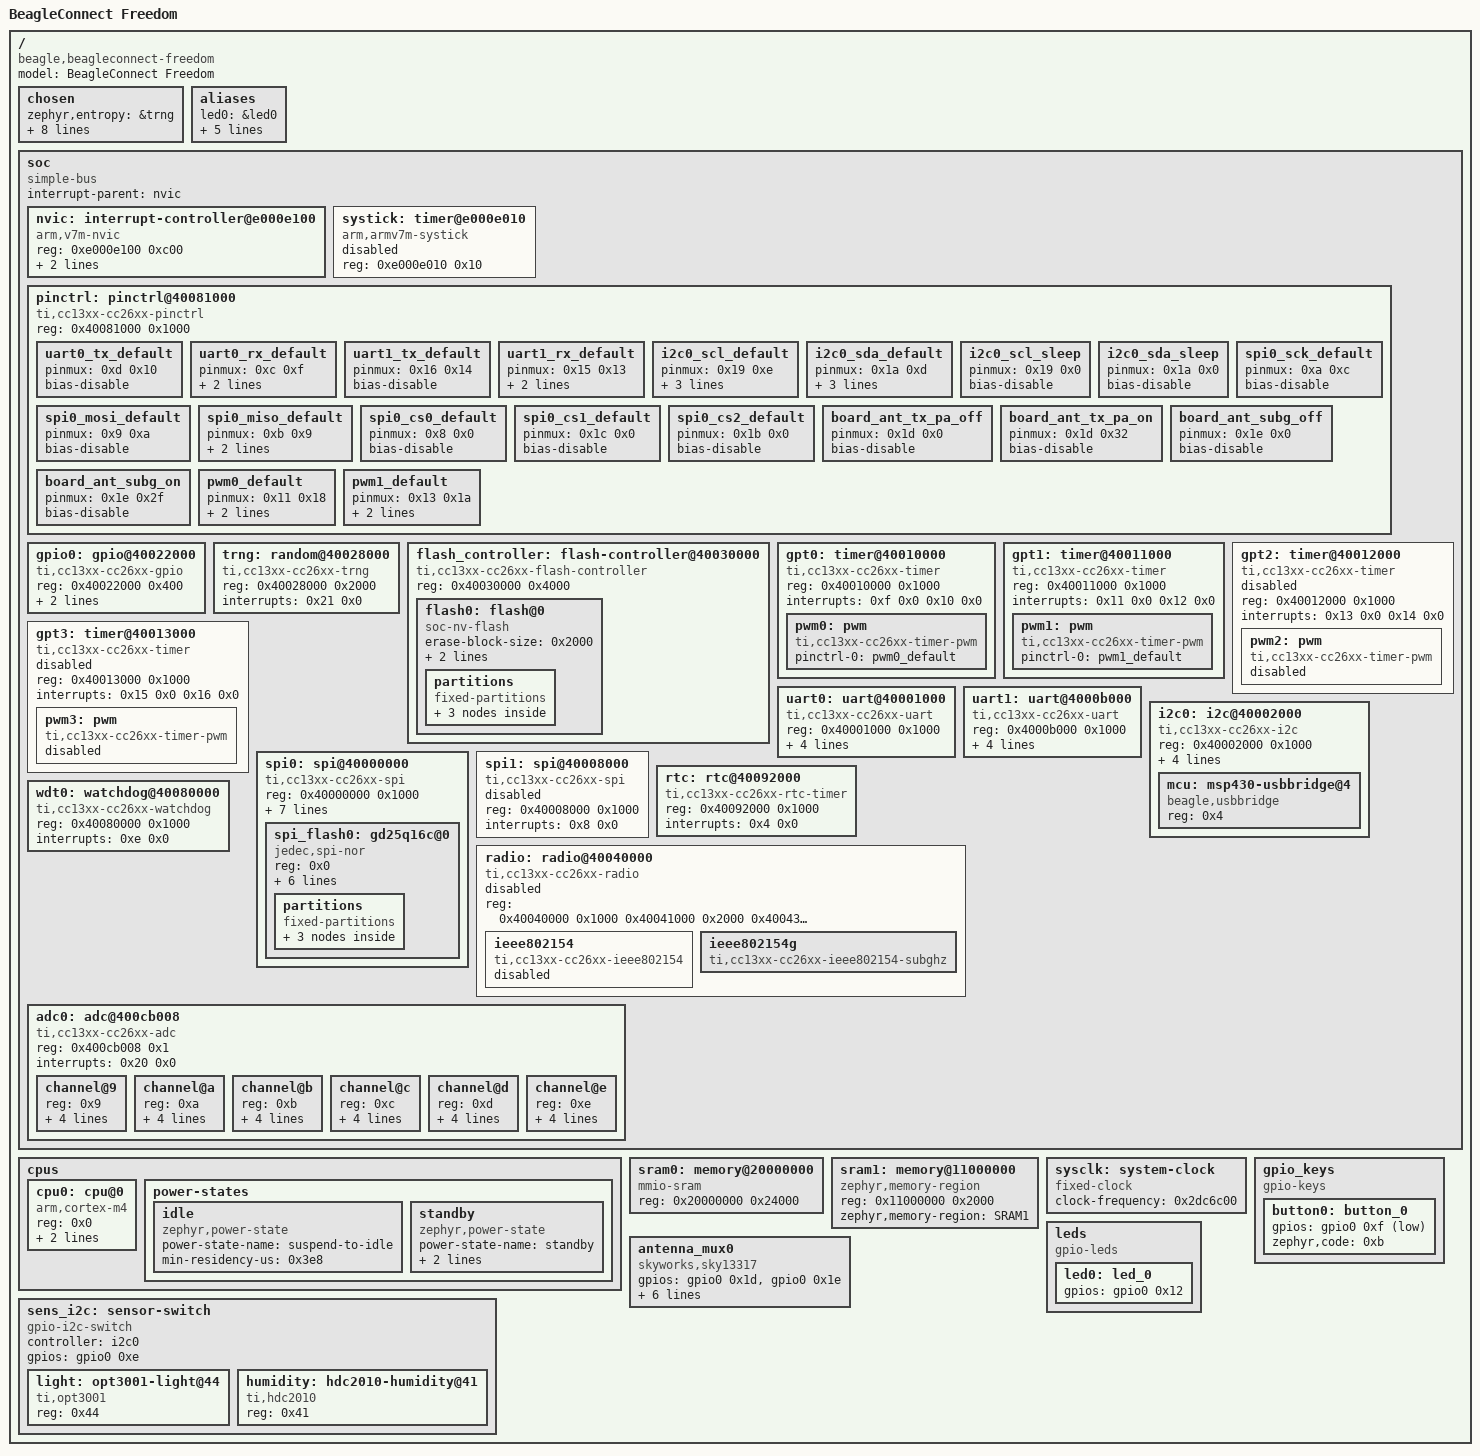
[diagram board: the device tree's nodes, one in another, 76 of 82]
/dts-v1/;

/* node '/' defined in zephyr/dts/common/skeleton.dtsi:9 */
/ {
	#address-cells = < 0x1 >;                    /* in zephyr/dts/common/skeleton.dtsi:10 */
	#size-cells = < 0x1 >;                       /* in zephyr/dts/common/skeleton.dtsi:11 */
	model = "BeagleConnect Freedom";             /* in zephyr/boards/beagle/beagleconnect_freedom/beagleconnect_freedom.dts:17 */
	compatible = "beagle,beagleconnect-freedom"; /* in zephyr/boards/beagle/beagleconnect_freedom/beagleconnect_freedom.dts:18 */

	/* node '/chosen' defined in zephyr/dts/common/skeleton.dtsi:13 */
	chosen {
		zephyr,entropy = &trng;                      /* in zephyr/dts/arm/ti/cc13xx_cc26xx.dtsi:15 */
		zephyr,flash-controller = &flash_controller; /* in zephyr/dts/arm/ti/cc13xx_cc26xx.dtsi:16 */
		zephyr,sram = &sram0;                        /* in zephyr/boards/beagle/beagleconnect_freedom/beagleconnect_freedom.dts:30 */
		zephyr,console = &uart0;                     /* in zephyr/boards/beagle/beagleconnect_freedom/beagleconnect_freedom.dts:31 */
		zephyr,shell-uart = &uart0;                  /* in zephyr/boards/beagle/beagleconnect_freedom/beagleconnect_freedom.dts:32 */
		zephyr,flash = &flash0;                      /* in zephyr/boards/beagle/beagleconnect_freedom/beagleconnect_freedom.dts:33 */
		zephyr,ieee802154 = &ieee802154g;            /* in zephyr/boards/beagle/beagleconnect_freedom/beagleconnect_freedom.dts:34 */
		zephyr,code-partition = &slot0_partition;    /* in zephyr/boards/beagle/beagleconnect_freedom/beagleconnect_freedom.dts:35 */
		zephyr,uart-mcumgr = &uart0;                 /* in zephyr/boards/beagle/beagleconnect_freedom/beagleconnect_freedom.dts:36 */
	};

	/* node '/aliases' defined in zephyr/dts/common/skeleton.dtsi:15 */
	aliases {
		led0 = &led0;               /* in zephyr/boards/beagle/beagleconnect_freedom/beagleconnect_freedom.dts:21 */
		sw0 = &button0;             /* in zephyr/boards/beagle/beagleconnect_freedom/beagleconnect_freedom.dts:22 */
		mcuboot-button0 = &button0; /* in zephyr/boards/beagle/beagleconnect_freedom/beagleconnect_freedom.dts:23 */
		sensor0 = &light;           /* in zephyr/boards/beagle/beagleconnect_freedom/beagleconnect_freedom.dts:24 */
		sensor1 = &humidity;        /* in zephyr/boards/beagle/beagleconnect_freedom/beagleconnect_freedom.dts:25 */
		watchdog0 = &wdt0;          /* in zephyr/boards/beagle/beagleconnect_freedom/beagleconnect_freedom.dts:26 */
	};

	/* node '/soc' defined in zephyr/dts/arm/armv7-m.dtsi:6 */
	soc {
		#address-cells = < 0x1 >;     /* in zephyr/dts/arm/armv7-m.dtsi:7 */
		#size-cells = < 0x1 >;        /* in zephyr/dts/arm/armv7-m.dtsi:8 */
		compatible = "simple-bus";    /* in zephyr/dts/arm/armv7-m.dtsi:9 */
		interrupt-parent = < &nvic >; /* in zephyr/dts/arm/armv7-m.dtsi:10 */
		ranges;                       /* in zephyr/dts/arm/armv7-m.dtsi:11 */

		/* node '/soc/interrupt-controller@e000e100' defined in zephyr/dts/arm/armv7-m.dtsi:13 */
		nvic: interrupt-controller@e000e100 {
			#address-cells = < 0x1 >;            /* in zephyr/dts/arm/armv7-m.dtsi:14 */
			compatible = "arm,v7m-nvic";         /* in zephyr/dts/arm/armv7-m.dtsi:15 */
			reg = < 0xe000e100 0xc00 >;          /* in zephyr/dts/arm/armv7-m.dtsi:16 */
			interrupt-controller;                /* in zephyr/dts/arm/armv7-m.dtsi:17 */
			#interrupt-cells = < 0x2 >;          /* in zephyr/dts/arm/armv7-m.dtsi:18 */
			arm,num-irq-priority-bits = < 0x3 >; /* in zephyr/dts/arm/ti/cc13xx_cc26xx.dtsi:246 */
			phandle = < 0x1 >;                   /* in zephyr/dts/arm/armv7-m.dtsi:10 */
		};

		/* node '/soc/timer@e000e010' defined in zephyr/dts/arm/armv7-m.dtsi:21 */
		systick: timer@e000e010 {
			compatible = "arm,armv7m-systick"; /* in zephyr/dts/arm/armv7-m.dtsi:22 */
			reg = < 0xe000e010 0x10 >;         /* in zephyr/dts/arm/armv7-m.dtsi:23 */
			status = "disabled";               /* in zephyr/dts/arm/ti/cc13xx_cc26xx.dtsi:250 */
		};

		/* node '/soc/pinctrl@40081000' defined in zephyr/dts/arm/ti/cc13xx_cc26xx.dtsi:64 */
		pinctrl: pinctrl@40081000 {
			compatible = "ti,cc13xx-cc26xx-pinctrl"; /* in zephyr/dts/arm/ti/cc13xx_cc26xx.dtsi:65 */
			reg = < 0x40081000 0x1000 >;             /* in zephyr/dts/arm/ti/cc13xx_cc26xx.dtsi:66 */

			/* node '/soc/pinctrl@40081000/uart0_tx_default' defined in zephyr/boards/beagle/beagleconnect_freedom/beagleconnect_freedom-pinctrl.dtsi:11 */
			uart0_tx_default: uart0_tx_default {
				pinmux = < 0xd 0x10 >; /* in zephyr/boards/beagle/beagleconnect_freedom/beagleconnect_freedom-pinctrl.dtsi:12 */
				bias-disable;          /* in zephyr/boards/beagle/beagleconnect_freedom/beagleconnect_freedom-pinctrl.dtsi:13 */
				phandle = < 0x6 >;     /* in zephyr/boards/beagle/beagleconnect_freedom/beagleconnect_freedom.dts:138 */
			};

			/* node '/soc/pinctrl@40081000/uart0_rx_default' defined in zephyr/boards/beagle/beagleconnect_freedom/beagleconnect_freedom-pinctrl.dtsi:16 */
			uart0_rx_default: uart0_rx_default {
				pinmux = < 0xc 0xf >; /* in zephyr/boards/beagle/beagleconnect_freedom/beagleconnect_freedom-pinctrl.dtsi:17 */
				bias-disable;         /* in zephyr/boards/beagle/beagleconnect_freedom/beagleconnect_freedom-pinctrl.dtsi:18 */
				input-enable;         /* in zephyr/boards/beagle/beagleconnect_freedom/beagleconnect_freedom-pinctrl.dtsi:19 */
				phandle = < 0x5 >;    /* in zephyr/boards/beagle/beagleconnect_freedom/beagleconnect_freedom.dts:138 */
			};

			/* node '/soc/pinctrl@40081000/uart1_tx_default' defined in zephyr/boards/beagle/beagleconnect_freedom/beagleconnect_freedom-pinctrl.dtsi:23 */
			uart1_tx_default: uart1_tx_default {
				pinmux = < 0x16 0x14 >; /* in zephyr/boards/beagle/beagleconnect_freedom/beagleconnect_freedom-pinctrl.dtsi:24 */
				bias-disable;           /* in zephyr/boards/beagle/beagleconnect_freedom/beagleconnect_freedom-pinctrl.dtsi:25 */
				phandle = < 0x8 >;      /* in zephyr/boards/beagle/beagleconnect_freedom/beagleconnect_freedom.dts:146 */
			};

			/* node '/soc/pinctrl@40081000/uart1_rx_default' defined in zephyr/boards/beagle/beagleconnect_freedom/beagleconnect_freedom-pinctrl.dtsi:28 */
			uart1_rx_default: uart1_rx_default {
				pinmux = < 0x15 0x13 >; /* in zephyr/boards/beagle/beagleconnect_freedom/beagleconnect_freedom-pinctrl.dtsi:29 */
				bias-disable;           /* in zephyr/boards/beagle/beagleconnect_freedom/beagleconnect_freedom-pinctrl.dtsi:30 */
				input-enable;           /* in zephyr/boards/beagle/beagleconnect_freedom/beagleconnect_freedom-pinctrl.dtsi:31 */
				phandle = < 0x7 >;      /* in zephyr/boards/beagle/beagleconnect_freedom/beagleconnect_freedom.dts:146 */
			};

			/* node '/soc/pinctrl@40081000/i2c0_scl_default' defined in zephyr/boards/beagle/beagleconnect_freedom/beagleconnect_freedom-pinctrl.dtsi:35 */
			i2c0_scl_default: i2c0_scl_default {
				pinmux = < 0x19 0xe >; /* in zephyr/boards/beagle/beagleconnect_freedom/beagleconnect_freedom-pinctrl.dtsi:36 */
				bias-pull-up;          /* in zephyr/boards/beagle/beagleconnect_freedom/beagleconnect_freedom-pinctrl.dtsi:37 */
				drive-open-drain;      /* in zephyr/boards/beagle/beagleconnect_freedom/beagleconnect_freedom-pinctrl.dtsi:38 */
				input-enable;          /* in zephyr/boards/beagle/beagleconnect_freedom/beagleconnect_freedom-pinctrl.dtsi:39 */
				phandle = < 0x9 >;     /* in zephyr/boards/beagle/beagleconnect_freedom/beagleconnect_freedom.dts:153 */
			};

			/* node '/soc/pinctrl@40081000/i2c0_sda_default' defined in zephyr/boards/beagle/beagleconnect_freedom/beagleconnect_freedom-pinctrl.dtsi:42 */
			i2c0_sda_default: i2c0_sda_default {
				pinmux = < 0x1a 0xd >; /* in zephyr/boards/beagle/beagleconnect_freedom/beagleconnect_freedom-pinctrl.dtsi:43 */
				bias-pull-up;          /* in zephyr/boards/beagle/beagleconnect_freedom/beagleconnect_freedom-pinctrl.dtsi:44 */
				drive-open-drain;      /* in zephyr/boards/beagle/beagleconnect_freedom/beagleconnect_freedom-pinctrl.dtsi:45 */
				input-enable;          /* in zephyr/boards/beagle/beagleconnect_freedom/beagleconnect_freedom-pinctrl.dtsi:46 */
				phandle = < 0xa >;     /* in zephyr/boards/beagle/beagleconnect_freedom/beagleconnect_freedom.dts:153 */
			};

			/* node '/soc/pinctrl@40081000/i2c0_scl_sleep' defined in zephyr/boards/beagle/beagleconnect_freedom/beagleconnect_freedom-pinctrl.dtsi:49 */
			i2c0_scl_sleep: i2c0_scl_sleep {
				pinmux = < 0x19 0x0 >; /* in zephyr/boards/beagle/beagleconnect_freedom/beagleconnect_freedom-pinctrl.dtsi:50 */
				bias-disable;          /* in zephyr/boards/beagle/beagleconnect_freedom/beagleconnect_freedom-pinctrl.dtsi:51 */
				phandle = < 0xb >;     /* in zephyr/boards/beagle/beagleconnect_freedom/beagleconnect_freedom.dts:154 */
			};

			/* node '/soc/pinctrl@40081000/i2c0_sda_sleep' defined in zephyr/boards/beagle/beagleconnect_freedom/beagleconnect_freedom-pinctrl.dtsi:54 */
			i2c0_sda_sleep: i2c0_sda_sleep {
				pinmux = < 0x1a 0x0 >; /* in zephyr/boards/beagle/beagleconnect_freedom/beagleconnect_freedom-pinctrl.dtsi:55 */
				bias-disable;          /* in zephyr/boards/beagle/beagleconnect_freedom/beagleconnect_freedom-pinctrl.dtsi:56 */
				phandle = < 0xc >;     /* in zephyr/boards/beagle/beagleconnect_freedom/beagleconnect_freedom.dts:154 */
			};

			/* node '/soc/pinctrl@40081000/spi0_sck_default' defined in zephyr/boards/beagle/beagleconnect_freedom/beagleconnect_freedom-pinctrl.dtsi:60 */
			spi0_sck_default: spi0_sck_default {
				pinmux = < 0xa 0xc >; /* in zephyr/boards/beagle/beagleconnect_freedom/beagleconnect_freedom-pinctrl.dtsi:61 */
				bias-disable;         /* in zephyr/boards/beagle/beagleconnect_freedom/beagleconnect_freedom-pinctrl.dtsi:62 */
				phandle = < 0xd >;    /* in zephyr/boards/beagle/beagleconnect_freedom/beagleconnect_freedom.dts:165 */
			};

			/* node '/soc/pinctrl@40081000/spi0_mosi_default' defined in zephyr/boards/beagle/beagleconnect_freedom/beagleconnect_freedom-pinctrl.dtsi:65 */
			spi0_mosi_default: spi0_mosi_default {
				pinmux = < 0x9 0xa >; /* in zephyr/boards/beagle/beagleconnect_freedom/beagleconnect_freedom-pinctrl.dtsi:66 */
				bias-disable;         /* in zephyr/boards/beagle/beagleconnect_freedom/beagleconnect_freedom-pinctrl.dtsi:67 */
				phandle = < 0xe >;    /* in zephyr/boards/beagle/beagleconnect_freedom/beagleconnect_freedom.dts:165 */
			};

			/* node '/soc/pinctrl@40081000/spi0_miso_default' defined in zephyr/boards/beagle/beagleconnect_freedom/beagleconnect_freedom-pinctrl.dtsi:70 */
			spi0_miso_default: spi0_miso_default {
				pinmux = < 0xb 0x9 >; /* in zephyr/boards/beagle/beagleconnect_freedom/beagleconnect_freedom-pinctrl.dtsi:71 */
				bias-disable;         /* in zephyr/boards/beagle/beagleconnect_freedom/beagleconnect_freedom-pinctrl.dtsi:72 */
				input-enable;         /* in zephyr/boards/beagle/beagleconnect_freedom/beagleconnect_freedom-pinctrl.dtsi:73 */
				phandle = < 0xf >;    /* in zephyr/boards/beagle/beagleconnect_freedom/beagleconnect_freedom.dts:165 */
			};

			/* node '/soc/pinctrl@40081000/spi0_cs0_default' defined in zephyr/boards/beagle/beagleconnect_freedom/beagleconnect_freedom-pinctrl.dtsi:76 */
			spi0_cs0_default: spi0_cs0_default {
				pinmux = < 0x8 0x0 >; /* in zephyr/boards/beagle/beagleconnect_freedom/beagleconnect_freedom-pinctrl.dtsi:77 */
				bias-disable;         /* in zephyr/boards/beagle/beagleconnect_freedom/beagleconnect_freedom-pinctrl.dtsi:78 */
				phandle = < 0x10 >;   /* in zephyr/boards/beagle/beagleconnect_freedom/beagleconnect_freedom.dts:165 */
			};

			/* node '/soc/pinctrl@40081000/spi0_cs1_default' defined in zephyr/boards/beagle/beagleconnect_freedom/beagleconnect_freedom-pinctrl.dtsi:81 */
			spi0_cs1_default: spi0_cs1_default {
				pinmux = < 0x1c 0x0 >; /* in zephyr/boards/beagle/beagleconnect_freedom/beagleconnect_freedom-pinctrl.dtsi:82 */
				bias-disable;          /* in zephyr/boards/beagle/beagleconnect_freedom/beagleconnect_freedom-pinctrl.dtsi:83 */
				phandle = < 0x11 >;    /* in zephyr/boards/beagle/beagleconnect_freedom/beagleconnect_freedom.dts:165 */
			};

			/* node '/soc/pinctrl@40081000/spi0_cs2_default' defined in zephyr/boards/beagle/beagleconnect_freedom/beagleconnect_freedom-pinctrl.dtsi:86 */
			spi0_cs2_default: spi0_cs2_default {
				pinmux = < 0x1b 0x0 >; /* in zephyr/boards/beagle/beagleconnect_freedom/beagleconnect_freedom-pinctrl.dtsi:87 */
				bias-disable;          /* in zephyr/boards/beagle/beagleconnect_freedom/beagleconnect_freedom-pinctrl.dtsi:88 */
				phandle = < 0x12 >;    /* in zephyr/boards/beagle/beagleconnect_freedom/beagleconnect_freedom.dts:165 */
			};

			/* node '/soc/pinctrl@40081000/board_ant_tx_pa_off' defined in zephyr/boards/beagle/beagleconnect_freedom/beagleconnect_freedom-pinctrl.dtsi:92 */
			board_ant_tx_pa_off: board_ant_tx_pa_off {
				pinmux = < 0x1d 0x0 >; /* in zephyr/boards/beagle/beagleconnect_freedom/beagleconnect_freedom-pinctrl.dtsi:93 */
				bias-disable;          /* in zephyr/boards/beagle/beagleconnect_freedom/beagleconnect_freedom-pinctrl.dtsi:94 */
				phandle = < 0x16 >;    /* in zephyr/boards/beagle/beagleconnect_freedom/beagleconnect_freedom.dts:64 */
			};

			/* node '/soc/pinctrl@40081000/board_ant_tx_pa_on' defined in zephyr/boards/beagle/beagleconnect_freedom/beagleconnect_freedom-pinctrl.dtsi:97 */
			board_ant_tx_pa_on: board_ant_tx_pa_on {
				pinmux = < 0x1d 0x32 >; /* in zephyr/boards/beagle/beagleconnect_freedom/beagleconnect_freedom-pinctrl.dtsi:98 */
				bias-disable;           /* in zephyr/boards/beagle/beagleconnect_freedom/beagleconnect_freedom-pinctrl.dtsi:99 */
				phandle = < 0x19 >;     /* in zephyr/boards/beagle/beagleconnect_freedom/beagleconnect_freedom.dts:66 */
			};

			/* node '/soc/pinctrl@40081000/board_ant_subg_off' defined in zephyr/boards/beagle/beagleconnect_freedom/beagleconnect_freedom-pinctrl.dtsi:102 */
			board_ant_subg_off: board_ant_subg_off {
				pinmux = < 0x1e 0x0 >; /* in zephyr/boards/beagle/beagleconnect_freedom/beagleconnect_freedom-pinctrl.dtsi:103 */
				bias-disable;          /* in zephyr/boards/beagle/beagleconnect_freedom/beagleconnect_freedom-pinctrl.dtsi:104 */
				phandle = < 0x17 >;    /* in zephyr/boards/beagle/beagleconnect_freedom/beagleconnect_freedom.dts:64 */
			};

			/* node '/soc/pinctrl@40081000/board_ant_subg_on' defined in zephyr/boards/beagle/beagleconnect_freedom/beagleconnect_freedom-pinctrl.dtsi:107 */
			board_ant_subg_on: board_ant_subg_on {
				pinmux = < 0x1e 0x2f >; /* in zephyr/boards/beagle/beagleconnect_freedom/beagleconnect_freedom-pinctrl.dtsi:108 */
				bias-disable;           /* in zephyr/boards/beagle/beagleconnect_freedom/beagleconnect_freedom-pinctrl.dtsi:109 */
				phandle = < 0x18 >;     /* in zephyr/boards/beagle/beagleconnect_freedom/beagleconnect_freedom.dts:65 */
			};

			/* node '/soc/pinctrl@40081000/pwm0_default' defined in zephyr/boards/beagle/beagleconnect_freedom/beagleconnect_freedom-pinctrl.dtsi:113 */
			pwm0_default: pwm0_default {
				pinmux = < 0x11 0x18 >;   /* in zephyr/boards/beagle/beagleconnect_freedom/beagleconnect_freedom-pinctrl.dtsi:114 */
				bias-disable;             /* in zephyr/boards/beagle/beagleconnect_freedom/beagleconnect_freedom-pinctrl.dtsi:115 */
				drive-strength = < 0x2 >; /* in zephyr/boards/beagle/beagleconnect_freedom/beagleconnect_freedom-pinctrl.dtsi:116 */
				phandle = < 0x2 >;        /* in zephyr/boards/beagle/beagleconnect_freedom/beagleconnect_freedom.dts:224 */
			};

			/* node '/soc/pinctrl@40081000/pwm1_default' defined in zephyr/boards/beagle/beagleconnect_freedom/beagleconnect_freedom-pinctrl.dtsi:120 */
			pwm1_default: pwm1_default {
				pinmux = < 0x13 0x1a >;   /* in zephyr/boards/beagle/beagleconnect_freedom/beagleconnect_freedom-pinctrl.dtsi:121 */
				bias-disable;             /* in zephyr/boards/beagle/beagleconnect_freedom/beagleconnect_freedom-pinctrl.dtsi:122 */
				drive-strength = < 0x2 >; /* in zephyr/boards/beagle/beagleconnect_freedom/beagleconnect_freedom-pinctrl.dtsi:123 */
				phandle = < 0x3 >;        /* in zephyr/boards/beagle/beagleconnect_freedom/beagleconnect_freedom.dts:230 */
			};
		};

		/* node '/soc/gpio@40022000' defined in zephyr/dts/arm/ti/cc13xx_cc26xx.dtsi:69 */
		gpio0: gpio@40022000 {
			compatible = "ti,cc13xx-cc26xx-gpio"; /* in zephyr/dts/arm/ti/cc13xx_cc26xx.dtsi:70 */
			reg = < 0x40022000 0x400 >;           /* in zephyr/dts/arm/ti/cc13xx_cc26xx.dtsi:71 */
			interrupts = < 0x0 0x0 >;             /* in zephyr/dts/arm/ti/cc13xx_cc26xx.dtsi:72 */
			gpio-controller;                      /* in zephyr/dts/arm/ti/cc13xx_cc26xx.dtsi:74 */
			#gpio-cells = < 0x2 >;                /* in zephyr/dts/arm/ti/cc13xx_cc26xx.dtsi:75 */
			status = "okay";                      /* in zephyr/boards/beagle/beagleconnect_freedom/beagleconnect_freedom.dts:131 */
			phandle = < 0x13 >;                   /* in zephyr/boards/beagle/beagleconnect_freedom/beagleconnect_freedom.dts:169 */
		};

		/* node '/soc/random@40028000' defined in zephyr/dts/arm/ti/cc13xx_cc26xx.dtsi:78 */
		trng: random@40028000 {
			compatible = "ti,cc13xx-cc26xx-trng"; /* in zephyr/dts/arm/ti/cc13xx_cc26xx.dtsi:79 */
			reg = < 0x40028000 0x2000 >;          /* in zephyr/dts/arm/ti/cc13xx_cc26xx.dtsi:80 */
			interrupts = < 0x21 0x0 >;            /* in zephyr/dts/arm/ti/cc13xx_cc26xx.dtsi:81 */
			status = "okay";                      /* in zephyr/boards/beagle/beagleconnect_freedom/beagleconnect_freedom.dts:127 */
		};

		/* node '/soc/flash-controller@40030000' defined in zephyr/dts/arm/ti/cc13xx_cc26xx.dtsi:85 */
		flash_controller: flash-controller@40030000 {
			compatible = "ti,cc13xx-cc26xx-flash-controller"; /* in zephyr/dts/arm/ti/cc13xx_cc26xx.dtsi:86 */
			reg = < 0x40030000 0x4000 >;                      /* in zephyr/dts/arm/ti/cc13xx_cc26xx.dtsi:87 */
			#address-cells = < 0x1 >;                         /* in zephyr/dts/arm/ti/cc13xx_cc26xx.dtsi:89 */
			#size-cells = < 0x1 >;                            /* in zephyr/dts/arm/ti/cc13xx_cc26xx.dtsi:90 */

			/* node '/soc/flash-controller@40030000/flash@0' defined in zephyr/dts/arm/ti/cc13xx_cc26xx.dtsi:92 */
			flash0: flash@0 {
				compatible = "soc-nv-flash";   /* in zephyr/dts/arm/ti/cc13xx_cc26xx.dtsi:93 */
				erase-block-size = < 0x2000 >; /* in zephyr/dts/arm/ti/cc13xx_cc26xx.dtsi:94 */
				write-block-size = < 0x1 >;    /* in zephyr/dts/arm/ti/cc13xx_cc26xx.dtsi:95 */
				reg = < 0x0 0xb0000 >;         /* in zephyr/dts/arm/ti/cc1352r7.dtsi:17 */

				/* node '/soc/flash-controller@40030000/flash@0/partitions' defined in zephyr/dts/arm/ti/cc1352r7.dtsi:19 */
				partitions {
					compatible = "fixed-partitions"; /* in zephyr/boards/beagle/beagleconnect_freedom/beagleconnect_freedom.dts:102 */
					#address-cells = < 0x1 >;        /* in zephyr/boards/beagle/beagleconnect_freedom/beagleconnect_freedom.dts:103 */
					#size-cells = < 0x1 >;           /* in zephyr/boards/beagle/beagleconnect_freedom/beagleconnect_freedom.dts:104 */

					/* node '/soc/flash-controller@40030000/flash@0/partitions/partition@affa8' defined in zephyr/dts/arm/ti/cc1352r7.dtsi:25 */
					ti_ccfg_partition: partition@affa8 {
						compatible = "zephyr,memory-region"; /* in zephyr/dts/arm/ti/cc1352r7.dtsi:26 */
						reg = < 0xaffa8 0x58 >;              /* in zephyr/dts/arm/ti/cc1352r7.dtsi:27 */
						zephyr,memory-region = "FLASH_CCFG"; /* in zephyr/dts/arm/ti/cc1352r7.dtsi:28 */
					};

					/* node '/soc/flash-controller@40030000/flash@0/partitions/partition@0' defined in zephyr/boards/beagle/beagleconnect_freedom/beagleconnect_freedom.dts:107 */
					boot_partition: partition@0 {
						label = "mcuboot";    /* in zephyr/boards/beagle/beagleconnect_freedom/beagleconnect_freedom.dts:108 */
						reg = < 0x0 0xe000 >; /* in zephyr/boards/beagle/beagleconnect_freedom/beagleconnect_freedom.dts:109 */
					};

					/* node '/soc/flash-controller@40030000/flash@0/partitions/partition@e000' defined in zephyr/boards/beagle/beagleconnect_freedom/beagleconnect_freedom.dts:113 */
					slot0_partition: partition@e000 {
						label = "image-0";        /* in zephyr/boards/beagle/beagleconnect_freedom/beagleconnect_freedom.dts:114 */
						reg = < 0xe000 0xa0000 >; /* in zephyr/boards/beagle/beagleconnect_freedom/beagleconnect_freedom.dts:115 */
					};
				};
			};
		};

		/* node '/soc/timer@40010000' defined in zephyr/dts/arm/ti/cc13xx_cc26xx.dtsi:99 */
		gpt0: timer@40010000 {
			compatible = "ti,cc13xx-cc26xx-timer"; /* in zephyr/dts/arm/ti/cc13xx_cc26xx.dtsi:100 */
			reg = < 0x40010000 0x1000 >;           /* in zephyr/dts/arm/ti/cc13xx_cc26xx.dtsi:101 */
			interrupts = < 0xf 0x0 0x10 0x0 >;     /* in zephyr/dts/arm/ti/cc13xx_cc26xx.dtsi:102 */
			interrupt-names = "gpt0a",
			                  "gpt0b";             /* in zephyr/dts/arm/ti/cc13xx_cc26xx.dtsi:103 */
			status = "okay";                       /* in zephyr/boards/beagle/beagleconnect_freedom/beagleconnect_freedom.dts:215 */

			/* node '/soc/timer@40010000/pwm' defined in zephyr/dts/arm/ti/cc13xx_cc26xx.dtsi:106 */
			pwm0: pwm {
				compatible = "ti,cc13xx-cc26xx-timer-pwm"; /* in zephyr/dts/arm/ti/cc13xx_cc26xx.dtsi:107 */
				#pwm-cells = < 0x3 >;                      /* in zephyr/dts/arm/ti/cc13xx_cc26xx.dtsi:108 */
				status = "okay";                           /* in zephyr/boards/beagle/beagleconnect_freedom/beagleconnect_freedom.dts:223 */
				pinctrl-0 = < &pwm0_default >;             /* in zephyr/boards/beagle/beagleconnect_freedom/beagleconnect_freedom.dts:224 */
				pinctrl-names = "default";                 /* in zephyr/boards/beagle/beagleconnect_freedom/beagleconnect_freedom.dts:225 */
			};
		};

		/* node '/soc/timer@40011000' defined in zephyr/dts/arm/ti/cc13xx_cc26xx.dtsi:113 */
		gpt1: timer@40011000 {
			compatible = "ti,cc13xx-cc26xx-timer"; /* in zephyr/dts/arm/ti/cc13xx_cc26xx.dtsi:114 */
			reg = < 0x40011000 0x1000 >;           /* in zephyr/dts/arm/ti/cc13xx_cc26xx.dtsi:115 */
			interrupts = < 0x11 0x0 0x12 0x0 >;    /* in zephyr/dts/arm/ti/cc13xx_cc26xx.dtsi:116 */
			interrupt-names = "gpt1a",
			                  "gpt1b";             /* in zephyr/dts/arm/ti/cc13xx_cc26xx.dtsi:117 */
			status = "okay";                       /* in zephyr/boards/beagle/beagleconnect_freedom/beagleconnect_freedom.dts:219 */

			/* node '/soc/timer@40011000/pwm' defined in zephyr/dts/arm/ti/cc13xx_cc26xx.dtsi:120 */
			pwm1: pwm {
				compatible = "ti,cc13xx-cc26xx-timer-pwm"; /* in zephyr/dts/arm/ti/cc13xx_cc26xx.dtsi:121 */
				#pwm-cells = < 0x3 >;                      /* in zephyr/dts/arm/ti/cc13xx_cc26xx.dtsi:122 */
				status = "okay";                           /* in zephyr/boards/beagle/beagleconnect_freedom/beagleconnect_freedom.dts:229 */
				pinctrl-0 = < &pwm1_default >;             /* in zephyr/boards/beagle/beagleconnect_freedom/beagleconnect_freedom.dts:230 */
				pinctrl-names = "default";                 /* in zephyr/boards/beagle/beagleconnect_freedom/beagleconnect_freedom.dts:231 */
			};
		};

		/* node '/soc/timer@40012000' defined in zephyr/dts/arm/ti/cc13xx_cc26xx.dtsi:127 */
		gpt2: timer@40012000 {
			compatible = "ti,cc13xx-cc26xx-timer"; /* in zephyr/dts/arm/ti/cc13xx_cc26xx.dtsi:128 */
			reg = < 0x40012000 0x1000 >;           /* in zephyr/dts/arm/ti/cc13xx_cc26xx.dtsi:129 */
			interrupts = < 0x13 0x0 0x14 0x0 >;    /* in zephyr/dts/arm/ti/cc13xx_cc26xx.dtsi:130 */
			interrupt-names = "gpt2a",
			                  "gpt2b";             /* in zephyr/dts/arm/ti/cc13xx_cc26xx.dtsi:131 */
			status = "disabled";                   /* in zephyr/dts/arm/ti/cc13xx_cc26xx.dtsi:132 */

			/* node '/soc/timer@40012000/pwm' defined in zephyr/dts/arm/ti/cc13xx_cc26xx.dtsi:134 */
			pwm2: pwm {
				compatible = "ti,cc13xx-cc26xx-timer-pwm"; /* in zephyr/dts/arm/ti/cc13xx_cc26xx.dtsi:135 */
				#pwm-cells = < 0x3 >;                      /* in zephyr/dts/arm/ti/cc13xx_cc26xx.dtsi:136 */
				status = "disabled";                       /* in zephyr/dts/arm/ti/cc13xx_cc26xx.dtsi:137 */
			};
		};

		/* node '/soc/timer@40013000' defined in zephyr/dts/arm/ti/cc13xx_cc26xx.dtsi:141 */
		gpt3: timer@40013000 {
			compatible = "ti,cc13xx-cc26xx-timer"; /* in zephyr/dts/arm/ti/cc13xx_cc26xx.dtsi:142 */
			reg = < 0x40013000 0x1000 >;           /* in zephyr/dts/arm/ti/cc13xx_cc26xx.dtsi:143 */
			interrupts = < 0x15 0x0 0x16 0x0 >;    /* in zephyr/dts/arm/ti/cc13xx_cc26xx.dtsi:144 */
			interrupt-names = "gpt3a",
			                  "gpt3b";             /* in zephyr/dts/arm/ti/cc13xx_cc26xx.dtsi:145 */
			status = "disabled";                   /* in zephyr/dts/arm/ti/cc13xx_cc26xx.dtsi:146 */

			/* node '/soc/timer@40013000/pwm' defined in zephyr/dts/arm/ti/cc13xx_cc26xx.dtsi:148 */
			pwm3: pwm {
				compatible = "ti,cc13xx-cc26xx-timer-pwm"; /* in zephyr/dts/arm/ti/cc13xx_cc26xx.dtsi:149 */
				#pwm-cells = < 0x3 >;                      /* in zephyr/dts/arm/ti/cc13xx_cc26xx.dtsi:150 */
				status = "disabled";                       /* in zephyr/dts/arm/ti/cc13xx_cc26xx.dtsi:151 */
			};
		};

		/* node '/soc/uart@40001000' defined in zephyr/dts/arm/ti/cc13xx_cc26xx.dtsi:155 */
		uart0: uart@40001000 {
			compatible = "ti,cc13xx-cc26xx-uart";                /* in zephyr/dts/arm/ti/cc13xx_cc26xx.dtsi:156 */
			reg = < 0x40001000 0x1000 >;                         /* in zephyr/dts/arm/ti/cc13xx_cc26xx.dtsi:157 */
			interrupts = < 0x5 0x0 >;                            /* in zephyr/dts/arm/ti/cc13xx_cc26xx.dtsi:158 */
			clocks = < &sysclk >;                                /* in zephyr/dts/arm/ti/cc13xx_cc26xx.dtsi:159 */
			status = "okay";                                     /* in zephyr/boards/beagle/beagleconnect_freedom/beagleconnect_freedom.dts:136 */
			current-speed = < 0x1c200 >;                         /* in zephyr/boards/beagle/beagleconnect_freedom/beagleconnect_freedom.dts:137 */
			pinctrl-0 = < &uart0_rx_default &uart0_tx_default >; /* in zephyr/boards/beagle/beagleconnect_freedom/beagleconnect_freedom.dts:138 */
			pinctrl-names = "default";                           /* in zephyr/boards/beagle/beagleconnect_freedom/beagleconnect_freedom.dts:139 */
		};

		/* node '/soc/uart@4000b000' defined in zephyr/dts/arm/ti/cc13xx_cc26xx.dtsi:163 */
		uart1: uart@4000b000 {
			compatible = "ti,cc13xx-cc26xx-uart";                /* in zephyr/dts/arm/ti/cc13xx_cc26xx.dtsi:164 */
			reg = < 0x4000b000 0x1000 >;                         /* in zephyr/dts/arm/ti/cc13xx_cc26xx.dtsi:165 */
			interrupts = < 0x24 0x0 >;                           /* in zephyr/dts/arm/ti/cc13xx_cc26xx.dtsi:166 */
			clocks = < &sysclk >;                                /* in zephyr/dts/arm/ti/cc13xx_cc26xx.dtsi:167 */
			status = "okay";                                     /* in zephyr/boards/beagle/beagleconnect_freedom/beagleconnect_freedom.dts:144 */
			current-speed = < 0x1c200 >;                         /* in zephyr/boards/beagle/beagleconnect_freedom/beagleconnect_freedom.dts:145 */
			pinctrl-0 = < &uart1_rx_default &uart1_tx_default >; /* in zephyr/boards/beagle/beagleconnect_freedom/beagleconnect_freedom.dts:146 */
			pinctrl-names = "default";                           /* in zephyr/boards/beagle/beagleconnect_freedom/beagleconnect_freedom.dts:147 */
		};

		/* node '/soc/i2c@40002000' defined in zephyr/dts/arm/ti/cc13xx_cc26xx.dtsi:171 */
		i2c0: i2c@40002000 {
			compatible = "ti,cc13xx-cc26xx-i2c";                 /* in zephyr/dts/arm/ti/cc13xx_cc26xx.dtsi:172 */
			#address-cells = < 0x1 >;                            /* in zephyr/dts/arm/ti/cc13xx_cc26xx.dtsi:173 */
			#size-cells = < 0x0 >;                               /* in zephyr/dts/arm/ti/cc13xx_cc26xx.dtsi:174 */
			reg = < 0x40002000 0x1000 >;                         /* in zephyr/dts/arm/ti/cc13xx_cc26xx.dtsi:175 */
			interrupts = < 0x1 0x0 >;                            /* in zephyr/dts/arm/ti/cc13xx_cc26xx.dtsi:176 */
			status = "okay";                                     /* in zephyr/boards/beagle/beagleconnect_freedom/beagleconnect_freedom.dts:151 */
			clock-frequency = < 0x61a80 >;                       /* in zephyr/boards/beagle/beagleconnect_freedom/beagleconnect_freedom.dts:152 */
			pinctrl-0 = < &i2c0_scl_default &i2c0_sda_default >; /* in zephyr/boards/beagle/beagleconnect_freedom/beagleconnect_freedom.dts:153 */
			pinctrl-1 = < &i2c0_scl_sleep &i2c0_sda_sleep >;     /* in zephyr/boards/beagle/beagleconnect_freedom/beagleconnect_freedom.dts:154 */
			pinctrl-names = "default",
			                "sleep";                             /* in zephyr/boards/beagle/beagleconnect_freedom/beagleconnect_freedom.dts:155 */
			phandle = < 0x1a >;                                  /* in zephyr/boards/beagle/beagleconnect_freedom/beagleconnect_freedom.dts:83 */

			/* node '/soc/i2c@40002000/msp430-usbbridge@4' defined in zephyr/boards/beagle/beagleconnect_freedom/beagleconnect_freedom.dts:157 */
			mcu: msp430-usbbridge@4 {
				compatible = "beagle,usbbridge"; /* in zephyr/boards/beagle/beagleconnect_freedom/beagleconnect_freedom.dts:158 */
				reg = < 0x4 >;                   /* in zephyr/boards/beagle/beagleconnect_freedom/beagleconnect_freedom.dts:159 */
			};
		};

		/* node '/soc/spi@40000000' defined in zephyr/dts/arm/ti/cc13xx_cc26xx.dtsi:181 */
		spi0: spi@40000000 {
			compatible = "ti,cc13xx-cc26xx-spi";                                                                      /* in zephyr/dts/arm/ti/cc13xx_cc26xx.dtsi:182 */
			#address-cells = < 0x1 >;                                                                                 /* in zephyr/dts/arm/ti/cc13xx_cc26xx.dtsi:183 */
			#size-cells = < 0x0 >;                                                                                    /* in zephyr/dts/arm/ti/cc13xx_cc26xx.dtsi:184 */
			reg = < 0x40000000 0x1000 >;                                                                              /* in zephyr/dts/arm/ti/cc13xx_cc26xx.dtsi:185 */
			interrupts = < 0x7 0x0 >;                                                                                 /* in zephyr/dts/arm/ti/cc13xx_cc26xx.dtsi:186 */
			status = "okay";                                                                                          /* in zephyr/boards/beagle/beagleconnect_freedom/beagleconnect_freedom.dts:164 */
			pinctrl-0 = < &spi0_sck_default &spi0_mosi_default &spi0_miso_default &spi0_cs0_default &spi0_cs1_default
			              &spi0_cs2_default >;                                                                        /* in zephyr/boards/beagle/beagleconnect_freedom/beagleconnect_freedom.dts:165 */
			pinctrl-names = "default";                                                                                /* in zephyr/boards/beagle/beagleconnect_freedom/beagleconnect_freedom.dts:168 */
			cs-gpios = < &gpio0 0x8 0x1 >,
			           < &gpio0 0x1c 0x1 >,
			           < &gpio0 0x1b 0x1 >;                                                                           /* in zephyr/boards/beagle/beagleconnect_freedom/beagleconnect_freedom.dts:169 */

			/* node '/soc/spi@40000000/gd25q16c@0' defined in zephyr/boards/beagle/beagleconnect_freedom/beagleconnect_freedom.dts:173 */
			spi_flash0: gd25q16c@0 {
				compatible = "jedec,spi-nor";     /* in zephyr/boards/beagle/beagleconnect_freedom/beagleconnect_freedom.dts:174 */
				reg = < 0x0 >;                    /* in zephyr/boards/beagle/beagleconnect_freedom/beagleconnect_freedom.dts:175 */
				spi-max-frequency = < 0x1e8480 >; /* in zephyr/boards/beagle/beagleconnect_freedom/beagleconnect_freedom.dts:176 */
				size = < 0x1000000 >;             /* in zephyr/boards/beagle/beagleconnect_freedom/beagleconnect_freedom.dts:178 */
				has-dpd;                          /* in zephyr/boards/beagle/beagleconnect_freedom/beagleconnect_freedom.dts:180 */
				t-enter-dpd = < 0x4e20 >;         /* in zephyr/boards/beagle/beagleconnect_freedom/beagleconnect_freedom.dts:181 */
				t-exit-dpd = < 0x186a0 >;         /* in zephyr/boards/beagle/beagleconnect_freedom/beagleconnect_freedom.dts:182 */
				jedec-id = [ C8 40 15 ];          /* in zephyr/boards/beagle/beagleconnect_freedom/beagleconnect_freedom.dts:183 */

				/* node '/soc/spi@40000000/gd25q16c@0/partitions' defined in zephyr/boards/beagle/beagleconnect_freedom/beagleconnect_freedom.dts:185 */
				partitions {
					compatible = "fixed-partitions"; /* in zephyr/boards/beagle/beagleconnect_freedom/beagleconnect_freedom.dts:186 */
					#address-cells = < 0x1 >;        /* in zephyr/boards/beagle/beagleconnect_freedom/beagleconnect_freedom.dts:187 */
					#size-cells = < 0x1 >;           /* in zephyr/boards/beagle/beagleconnect_freedom/beagleconnect_freedom.dts:188 */

					/* node '/soc/spi@40000000/gd25q16c@0/partitions/partition@0' defined in zephyr/boards/beagle/beagleconnect_freedom/beagleconnect_freedom.dts:191 */
					slot1_partition: partition@0 {
						label = "image-1";     /* in zephyr/boards/beagle/beagleconnect_freedom/beagleconnect_freedom.dts:192 */
						reg = < 0x0 0xa0000 >; /* in zephyr/boards/beagle/beagleconnect_freedom/beagleconnect_freedom.dts:193 */
					};

					/* node '/soc/spi@40000000/gd25q16c@0/partitions/partition@A0000' defined in zephyr/boards/beagle/beagleconnect_freedom/beagleconnect_freedom.dts:197 */
					scratch_partition: partition@A0000 {
						label = "image-scratch";   /* in zephyr/boards/beagle/beagleconnect_freedom/beagleconnect_freedom.dts:198 */
						reg = < 0xa0000 0x20000 >; /* in zephyr/boards/beagle/beagleconnect_freedom/beagleconnect_freedom.dts:199 */
					};

					/* node '/soc/spi@40000000/gd25q16c@0/partitions/partition@c0000' defined in zephyr/boards/beagle/beagleconnect_freedom/beagleconnect_freedom.dts:202 */
					storage_partition: partition@c0000 {
						label = "storage";          /* in zephyr/boards/beagle/beagleconnect_freedom/beagleconnect_freedom.dts:203 */
						reg = < 0xc0000 0x140000 >; /* in zephyr/boards/beagle/beagleconnect_freedom/beagleconnect_freedom.dts:204 */
					};
				};
			};
		};

		/* node '/soc/spi@40008000' defined in zephyr/dts/arm/ti/cc13xx_cc26xx.dtsi:190 */
		spi1: spi@40008000 {
			compatible = "ti,cc13xx-cc26xx-spi"; /* in zephyr/dts/arm/ti/cc13xx_cc26xx.dtsi:191 */
			#address-cells = < 0x1 >;            /* in zephyr/dts/arm/ti/cc13xx_cc26xx.dtsi:192 */
			#size-cells = < 0x0 >;               /* in zephyr/dts/arm/ti/cc13xx_cc26xx.dtsi:193 */
			reg = < 0x40008000 0x1000 >;         /* in zephyr/dts/arm/ti/cc13xx_cc26xx.dtsi:194 */
			interrupts = < 0x8 0x0 >;            /* in zephyr/dts/arm/ti/cc13xx_cc26xx.dtsi:195 */
			status = "disabled";                 /* in zephyr/dts/arm/ti/cc13xx_cc26xx.dtsi:196 */
		};

		/* node '/soc/rtc@40092000' defined in zephyr/dts/arm/ti/cc13xx_cc26xx.dtsi:200 */
		rtc: rtc@40092000 {
			compatible = "ti,cc13xx-cc26xx-rtc-timer"; /* in zephyr/dts/arm/ti/cc13xx_cc26xx.dtsi:201 */
			reg = < 0x40092000 0x1000 >;               /* in zephyr/dts/arm/ti/cc13xx_cc26xx.dtsi:202 */
			interrupts = < 0x4 0x0 >;                  /* in zephyr/dts/arm/ti/cc13xx_cc26xx.dtsi:203 */
			status = "okay";                           /* in zephyr/dts/arm/ti/cc13xx_cc26xx.dtsi:204 */
		};

		/* node '/soc/radio@40040000' defined in zephyr/dts/arm/ti/cc13xx_cc26xx.dtsi:207 */
		radio: radio@40040000 {
			compatible = "ti,cc13xx-cc26xx-radio";                                             /* in zephyr/dts/arm/ti/cc13xx_cc26xx.dtsi:208 */
			status = "disabled";                                                               /* in zephyr/dts/arm/ti/cc13xx_cc26xx.dtsi:209 */
			reg = < 0x40040000 0x1000 0x40041000 0x2000 0x40043000 0x1000 0x40044000 0x1000 >; /* in zephyr/dts/arm/ti/cc13xx_cc26xx.dtsi:211 */
			reg-names = "RFC_PWR",
			            "RFC_DBELL",
			            "RFC_RAT",
			            "RFC_FSCA";                                                            /* in zephyr/dts/arm/ti/cc13xx_cc26xx.dtsi:215 */

			/* node '/soc/radio@40040000/ieee802154' defined in zephyr/dts/arm/ti/cc13xx_cc26xx.dtsi:217 */
			ieee802154: ieee802154 {
				compatible = "ti,cc13xx-cc26xx-ieee802154"; /* in zephyr/dts/arm/ti/cc13xx_cc26xx.dtsi:218 */
				status = "disabled";                        /* in zephyr/dts/arm/ti/cc13xx_cc26xx.dtsi:219 */
			};

			/* node '/soc/radio@40040000/ieee802154g' defined in zephyr/dts/arm/ti/cc13xx_cc26xx.dtsi:222 */
			ieee802154g: ieee802154g {
				compatible = "ti,cc13xx-cc26xx-ieee802154-subghz"; /* in zephyr/dts/arm/ti/cc13xx_cc26xx.dtsi:223 */
				status = "okay";                                   /* in zephyr/boards/beagle/beagleconnect_freedom/beagleconnect_freedom.dts:211 */
			};
		};

		/* node '/soc/watchdog@40080000' defined in zephyr/dts/arm/ti/cc13xx_cc26xx.dtsi:228 */
		wdt0: watchdog@40080000 {
			compatible = "ti,cc13xx-cc26xx-watchdog"; /* in zephyr/dts/arm/ti/cc13xx_cc26xx.dtsi:229 */
			reg = < 0x40080000 0x1000 >;              /* in zephyr/dts/arm/ti/cc13xx_cc26xx.dtsi:230 */
			interrupts = < 0xe 0x0 >;                 /* in zephyr/dts/arm/ti/cc13xx_cc26xx.dtsi:231 */
			status = "okay";                          /* in zephyr/boards/beagle/beagleconnect_freedom/beagleconnect_freedom.dts:296 */
		};

		/* node '/soc/adc@400cb008' defined in zephyr/dts/arm/ti/cc13xx_cc26xx.dtsi:235 */
		adc0: adc@400cb008 {
			compatible = "ti,cc13xx-cc26xx-adc"; /* in zephyr/dts/arm/ti/cc13xx_cc26xx.dtsi:236 */
			reg = < 0x400cb008 0x1 >;            /* in zephyr/dts/arm/ti/cc13xx_cc26xx.dtsi:237 */
			interrupts = < 0x20 0x0 >;           /* in zephyr/dts/arm/ti/cc13xx_cc26xx.dtsi:238 */
			#io-channel-cells = < 0x1 >;         /* in zephyr/dts/arm/ti/cc13xx_cc26xx.dtsi:240 */
			status = "okay";                     /* in zephyr/boards/beagle/beagleconnect_freedom/beagleconnect_freedom.dts:235 */
			#address-cells = < 0x1 >;            /* in zephyr/boards/beagle/beagleconnect_freedom/beagleconnect_freedom.dts:237 */
			#size-cells = < 0x0 >;               /* in zephyr/boards/beagle/beagleconnect_freedom/beagleconnect_freedom.dts:238 */

			/* node '/soc/adc@400cb008/channel@9' defined in zephyr/boards/beagle/beagleconnect_freedom/beagleconnect_freedom.dts:241 */
			channel@9 {
				reg = < 0x9 >;                         /* in zephyr/boards/beagle/beagleconnect_freedom/beagleconnect_freedom.dts:242 */
				zephyr,gain = "ADC_GAIN_1";            /* in zephyr/boards/beagle/beagleconnect_freedom/beagleconnect_freedom.dts:243 */
				zephyr,reference = "ADC_REF_INTERNAL"; /* in zephyr/boards/beagle/beagleconnect_freedom/beagleconnect_freedom.dts:244 */
				zephyr,acquisition-time = < 0x0 >;     /* in zephyr/boards/beagle/beagleconnect_freedom/beagleconnect_freedom.dts:245 */
				zephyr,resolution = < 0xc >;           /* in zephyr/boards/beagle/beagleconnect_freedom/beagleconnect_freedom.dts:246 */
			};

			/* node '/soc/adc@400cb008/channel@a' defined in zephyr/boards/beagle/beagleconnect_freedom/beagleconnect_freedom.dts:250 */
			channel@a {
				reg = < 0xa >;                         /* in zephyr/boards/beagle/beagleconnect_freedom/beagleconnect_freedom.dts:251 */
				zephyr,gain = "ADC_GAIN_1";            /* in zephyr/boards/beagle/beagleconnect_freedom/beagleconnect_freedom.dts:252 */
				zephyr,reference = "ADC_REF_INTERNAL"; /* in zephyr/boards/beagle/beagleconnect_freedom/beagleconnect_freedom.dts:253 */
				zephyr,acquisition-time = < 0x0 >;     /* in zephyr/boards/beagle/beagleconnect_freedom/beagleconnect_freedom.dts:254 */
				zephyr,resolution = < 0xc >;           /* in zephyr/boards/beagle/beagleconnect_freedom/beagleconnect_freedom.dts:255 */
			};

			/* node '/soc/adc@400cb008/channel@b' defined in zephyr/boards/beagle/beagleconnect_freedom/beagleconnect_freedom.dts:259 */
			channel@b {
				reg = < 0xb >;                         /* in zephyr/boards/beagle/beagleconnect_freedom/beagleconnect_freedom.dts:260 */
				zephyr,gain = "ADC_GAIN_1";            /* in zephyr/boards/beagle/beagleconnect_freedom/beagleconnect_freedom.dts:261 */
				zephyr,reference = "ADC_REF_INTERNAL"; /* in zephyr/boards/beagle/beagleconnect_freedom/beagleconnect_freedom.dts:262 */
				zephyr,acquisition-time = < 0x0 >;     /* in zephyr/boards/beagle/beagleconnect_freedom/beagleconnect_freedom.dts:263 */
				zephyr,resolution = < 0xc >;           /* in zephyr/boards/beagle/beagleconnect_freedom/beagleconnect_freedom.dts:264 */
			};

			/* node '/soc/adc@400cb008/channel@c' defined in zephyr/boards/beagle/beagleconnect_freedom/beagleconnect_freedom.dts:268 */
			channel@c {
				reg = < 0xc >;                         /* in zephyr/boards/beagle/beagleconnect_freedom/beagleconnect_freedom.dts:269 */
				zephyr,gain = "ADC_GAIN_1";            /* in zephyr/boards/beagle/beagleconnect_freedom/beagleconnect_freedom.dts:270 */
				zephyr,reference = "ADC_REF_INTERNAL"; /* in zephyr/boards/beagle/beagleconnect_freedom/beagleconnect_freedom.dts:271 */
				zephyr,acquisition-time = < 0x0 >;     /* in zephyr/boards/beagle/beagleconnect_freedom/beagleconnect_freedom.dts:272 */
				zephyr,resolution = < 0xc >;           /* in zephyr/boards/beagle/beagleconnect_freedom/beagleconnect_freedom.dts:273 */
			};

			/* node '/soc/adc@400cb008/channel@d' defined in zephyr/boards/beagle/beagleconnect_freedom/beagleconnect_freedom.dts:277 */
			channel@d {
				reg = < 0xd >;                         /* in zephyr/boards/beagle/beagleconnect_freedom/beagleconnect_freedom.dts:278 */
				zephyr,gain = "ADC_GAIN_1";            /* in zephyr/boards/beagle/beagleconnect_freedom/beagleconnect_freedom.dts:279 */
				zephyr,reference = "ADC_REF_INTERNAL"; /* in zephyr/boards/beagle/beagleconnect_freedom/beagleconnect_freedom.dts:280 */
				zephyr,acquisition-time = < 0x0 >;     /* in zephyr/boards/beagle/beagleconnect_freedom/beagleconnect_freedom.dts:281 */
				zephyr,resolution = < 0xc >;           /* in zephyr/boards/beagle/beagleconnect_freedom/beagleconnect_freedom.dts:282 */
			};

			/* node '/soc/adc@400cb008/channel@e' defined in zephyr/boards/beagle/beagleconnect_freedom/beagleconnect_freedom.dts:286 */
			channel@e {
				reg = < 0xe >;                         /* in zephyr/boards/beagle/beagleconnect_freedom/beagleconnect_freedom.dts:287 */
				zephyr,gain = "ADC_GAIN_1";            /* in zephyr/boards/beagle/beagleconnect_freedom/beagleconnect_freedom.dts:288 */
				zephyr,reference = "ADC_REF_INTERNAL"; /* in zephyr/boards/beagle/beagleconnect_freedom/beagleconnect_freedom.dts:289 */
				zephyr,acquisition-time = < 0x0 >;     /* in zephyr/boards/beagle/beagleconnect_freedom/beagleconnect_freedom.dts:290 */
				zephyr,resolution = < 0xc >;           /* in zephyr/boards/beagle/beagleconnect_freedom/beagleconnect_freedom.dts:291 */
			};
		};
	};

	/* node '/cpus' defined in zephyr/dts/arm/ti/cc13xx_cc26xx.dtsi:19 */
	cpus {
		#address-cells = < 0x1 >; /* in zephyr/dts/arm/ti/cc13xx_cc26xx.dtsi:20 */
		#size-cells = < 0x0 >;    /* in zephyr/dts/arm/ti/cc13xx_cc26xx.dtsi:21 */

		/* node '/cpus/cpu@0' defined in zephyr/dts/arm/ti/cc13xx_cc26xx.dtsi:23 */
		cpu0: cpu@0 {
			device_type = "cpu";                   /* in zephyr/dts/arm/ti/cc13xx_cc26xx.dtsi:24 */
			compatible = "arm,cortex-m4";          /* in zephyr/dts/arm/ti/cc13xx_cc26xx.dtsi:25 */
			reg = < 0x0 >;                         /* in zephyr/dts/arm/ti/cc13xx_cc26xx.dtsi:26 */
			cpu-power-states = < &idle &standby >; /* in zephyr/dts/arm/ti/cc13xx_cc26xx.dtsi:27 */
			clock-frequency = < 0x2dc6c00 >;       /* in zephyr/boards/beagle/beagleconnect_freedom/beagleconnect_freedom.dts:123 */
		};

		/* node '/cpus/power-states' defined in zephyr/dts/arm/ti/cc13xx_cc26xx.dtsi:30 */
		power-states {

			/* node '/cpus/power-states/idle' defined in zephyr/dts/arm/ti/cc13xx_cc26xx.dtsi:31 */
			idle: idle {
				compatible = "zephyr,power-state";    /* in zephyr/dts/arm/ti/cc13xx_cc26xx.dtsi:32 */
				power-state-name = "suspend-to-idle"; /* in zephyr/dts/arm/ti/cc13xx_cc26xx.dtsi:33 */
				min-residency-us = < 0x3e8 >;         /* in zephyr/dts/arm/ti/cc13xx_cc26xx.dtsi:34 */
				phandle = < 0x14 >;                   /* in zephyr/dts/arm/ti/cc13xx_cc26xx.dtsi:27 */
			};

			/* node '/cpus/power-states/standby' defined in zephyr/dts/arm/ti/cc13xx_cc26xx.dtsi:37 */
			standby: standby {
				compatible = "zephyr,power-state"; /* in zephyr/dts/arm/ti/cc13xx_cc26xx.dtsi:38 */
				power-state-name = "standby";      /* in zephyr/dts/arm/ti/cc13xx_cc26xx.dtsi:39 */
				min-residency-us = < 0x1388 >;     /* in zephyr/dts/arm/ti/cc13xx_cc26xx.dtsi:40 */
				exit-latency-us = < 0xf0 >;        /* in zephyr/dts/arm/ti/cc13xx_cc26xx.dtsi:41 */
				phandle = < 0x15 >;                /* in zephyr/dts/arm/ti/cc13xx_cc26xx.dtsi:27 */
			};
		};
	};

	/* node '/memory@20000000' defined in zephyr/dts/arm/ti/cc13xx_cc26xx.dtsi:46 */
	sram0: memory@20000000 {
		compatible = "mmio-sram";     /* in zephyr/dts/arm/ti/cc13xx_cc26xx.dtsi:47 */
		reg = < 0x20000000 0x24000 >; /* in zephyr/dts/arm/ti/cc1352r7.dtsi:12 */
	};

	/* node '/memory@11000000' defined in zephyr/dts/arm/ti/cc13xx_cc26xx.dtsi:51 */
	sram1: memory@11000000 {
		compatible = "zephyr,memory-region",
		             "mmio-sram";            /* in zephyr/dts/arm/ti/cc13xx_cc26xx.dtsi:52 */
		reg = < 0x11000000 0x2000 >;         /* in zephyr/dts/arm/ti/cc13xx_cc26xx.dtsi:53 */
		zephyr,memory-region = "SRAM1";      /* in zephyr/dts/arm/ti/cc13xx_cc26xx.dtsi:54 */
	};

	/* node '/system-clock' defined in zephyr/dts/arm/ti/cc13xx_cc26xx.dtsi:57 */
	sysclk: system-clock {
		compatible = "fixed-clock";      /* in zephyr/dts/arm/ti/cc13xx_cc26xx.dtsi:58 */
		clock-frequency = < 0x2dc6c00 >; /* in zephyr/dts/arm/ti/cc13xx_cc26xx.dtsi:59 */
		#clock-cells = < 0x0 >;          /* in zephyr/dts/arm/ti/cc13xx_cc26xx.dtsi:60 */
		phandle = < 0x4 >;               /* in zephyr/dts/arm/ti/cc13xx_cc26xx.dtsi:159 */
	};

	/* node '/gpio_keys' defined in zephyr/boards/beagle/beagleconnect_freedom/beagleconnect_freedom.dts:39 */
	gpio_keys {
		compatible = "gpio-keys"; /* in zephyr/boards/beagle/beagleconnect_freedom/beagleconnect_freedom.dts:40 */

		/* node '/gpio_keys/button_0' defined in zephyr/boards/beagle/beagleconnect_freedom/beagleconnect_freedom.dts:42 */
		button0: button_0 {
			gpios = < &gpio0 0xf 0x1 >; /* in zephyr/boards/beagle/beagleconnect_freedom/beagleconnect_freedom.dts:43 */
			zephyr,code = < 0xb >;      /* in zephyr/boards/beagle/beagleconnect_freedom/beagleconnect_freedom.dts:44 */
		};
	};

	/* node '/antenna_mux0' defined in zephyr/boards/beagle/beagleconnect_freedom/beagleconnect_freedom.dts:60 */
	antenna_mux0: antenna_mux0 {
		compatible = "skyworks,sky13317";                         /* in zephyr/boards/beagle/beagleconnect_freedom/beagleconnect_freedom.dts:61 */
		status = "okay";                                          /* in zephyr/boards/beagle/beagleconnect_freedom/beagleconnect_freedom.dts:62 */
		gpios = < &gpio0 0x1d 0x0 >,
		        < &gpio0 0x1e 0x0 >;                              /* in zephyr/boards/beagle/beagleconnect_freedom/beagleconnect_freedom.dts:63 */
		pinctrl-0 = < &board_ant_tx_pa_off &board_ant_subg_off >; /* in zephyr/boards/beagle/beagleconnect_freedom/beagleconnect_freedom.dts:64 */
		pinctrl-1 = < &board_ant_tx_pa_off &board_ant_subg_on >;  /* in zephyr/boards/beagle/beagleconnect_freedom/beagleconnect_freedom.dts:65 */
		pinctrl-2 = < &board_ant_tx_pa_on &board_ant_subg_on >;   /* in zephyr/boards/beagle/beagleconnect_freedom/beagleconnect_freedom.dts:66 */
		pinctrl-names = "default",
		                "ant_subg",
		                "ant_subg_pa";                            /* in zephyr/boards/beagle/beagleconnect_freedom/beagleconnect_freedom.dts:67 */
	};

	/* node '/leds' defined in zephyr/boards/beagle/beagleconnect_freedom/beagleconnect_freedom.dts:70 */
	leds: leds {
		compatible = "gpio-leds"; /* in zephyr/boards/beagle/beagleconnect_freedom/beagleconnect_freedom.dts:71 */

		/* node '/leds/led_0' defined in zephyr/boards/beagle/beagleconnect_freedom/beagleconnect_freedom.dts:73 */
		led0: led_0 {
			gpios = < &gpio0 0x12 0x0 >; /* in zephyr/boards/beagle/beagleconnect_freedom/beagleconnect_freedom.dts:74 */
		};
	};

	/* node '/sensor-switch' defined in zephyr/boards/beagle/beagleconnect_freedom/beagleconnect_freedom.dts:78 */
	sens_i2c: sensor-switch {
		status = "okay";                /* in zephyr/boards/beagle/beagleconnect_freedom/beagleconnect_freedom.dts:79 */
		compatible = "gpio-i2c-switch"; /* in zephyr/boards/beagle/beagleconnect_freedom/beagleconnect_freedom.dts:80 */
		#address-cells = < 0x1 >;       /* in zephyr/boards/beagle/beagleconnect_freedom/beagleconnect_freedom.dts:81 */
		#size-cells = < 0x0 >;          /* in zephyr/boards/beagle/beagleconnect_freedom/beagleconnect_freedom.dts:82 */
		controller = < &i2c0 >;         /* in zephyr/boards/beagle/beagleconnect_freedom/beagleconnect_freedom.dts:83 */
		gpios = < &gpio0 0xe 0x0 >;     /* in zephyr/boards/beagle/beagleconnect_freedom/beagleconnect_freedom.dts:84 */

		/* node '/sensor-switch/opt3001-light@44' defined in zephyr/boards/beagle/beagleconnect_freedom/beagleconnect_freedom.dts:86 */
		light: opt3001-light@44 {
			status = "okay";           /* in zephyr/boards/beagle/beagleconnect_freedom/beagleconnect_freedom.dts:87 */
			compatible = "ti,opt3001"; /* in zephyr/boards/beagle/beagleconnect_freedom/beagleconnect_freedom.dts:88 */
			reg = < 0x44 >;            /* in zephyr/boards/beagle/beagleconnect_freedom/beagleconnect_freedom.dts:89 */
		};

		/* node '/sensor-switch/hdc2010-humidity@41' defined in zephyr/boards/beagle/beagleconnect_freedom/beagleconnect_freedom.dts:92 */
		humidity: hdc2010-humidity@41 {
			status = "okay";           /* in zephyr/boards/beagle/beagleconnect_freedom/beagleconnect_freedom.dts:93 */
			compatible = "ti,hdc2010"; /* in zephyr/boards/beagle/beagleconnect_freedom/beagleconnect_freedom.dts:94 */
			reg = < 0x41 >;            /* in zephyr/boards/beagle/beagleconnect_freedom/beagleconnect_freedom.dts:95 */
		};
	};
};
